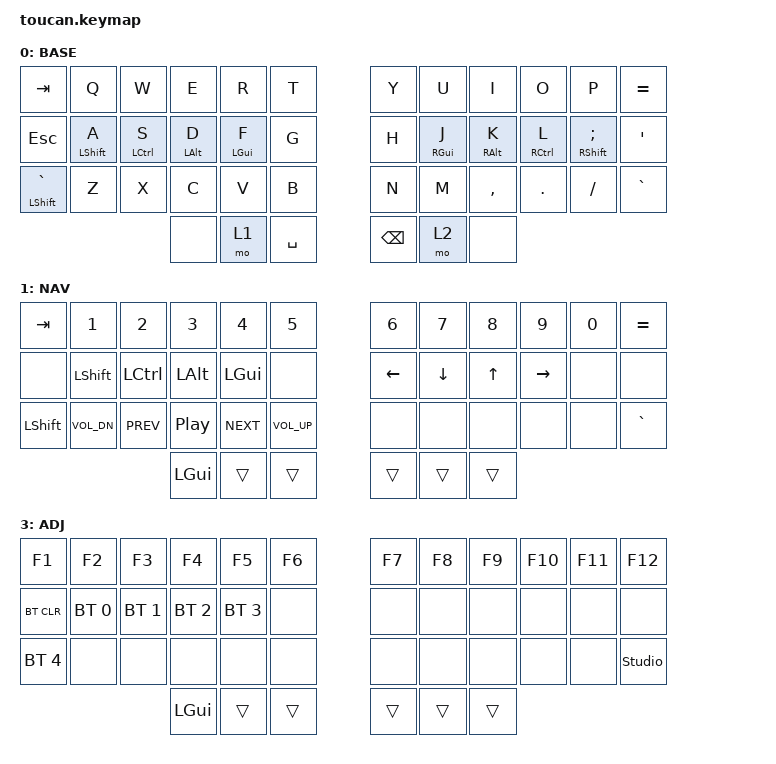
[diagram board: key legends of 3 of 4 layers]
#include <behaviors.dtsi>
#include <dt-bindings/zmk/keys.h>
#include <dt-bindings/zmk/bt.h>
#include <dt-bindings/zmk/outputs.h>

#define BASE 0
#define NAV  1
#define SYM  2
#define ADJ  3

#define SFT_A &mt LSHIFT A
#define CTRL_S &mt LCTRL S
#define ALT_D &mt LALT D
#define GUI_F &mt LGUI F

#define GUI_J &mt RGUI J
#define ALT_K &mt RALT K
#define CTRL_L &mt RCTRL L
#define SFT_SEMI &mt RSHIFT SEMI

#define SFT_GRAVE &mt LSHIFT GRAVE


&mt {
    flavor = "tap-preferred";
    tapping-term-ms = <180>;
};

/ {
    combos {
        compatible = "zmk,combos";
        combo_esc {
            timeout-ms = <50>;
            key-positions = <38 39>;
            bindings = <&kp RET>;
        };
    };
};

/ {
    conditional_layers {
        compatible = "zmk,conditional-layers";
        tri_layer {
            if-layers = <1 2>;
            then-layer = <3>;
        };
    };

    keymap {
        compatible = "zmk,keymap";

        base {
            display-name = "BASE";
            bindings = <
                &kp TAB   &kp Q &kp W  &kp E &kp R &kp T      &kp Y    &kp U  &kp I     &kp O   &kp P    &kp EQUAL
                &kp ESC   SFT_A CTRL_S ALT_D GUI_F &kp G      &kp H    GUI_J  ALT_K     CTRL_L  SFT_SEMI &kp SQT
                SFT_GRAVE &kp Z &kp X  &kp C &kp V &kp B      &kp N    &kp M  &kp COMMA &kp DOT &kp FSLH &kp GRAVE
                                       &none &mo 1 &kp SPACE  &kp BSPC &mo 2  &none
            >;
        };

        nav {
            display-name = "NAV";
            bindings = <
                &kp TAB     &kp N1          &kp N2       &kp N3           &kp N4       &kp N5                &kp N6   &kp N7   &kp N8 &kp N9    &kp N0 &kp EQUAL
                &none       &kp LSHIFT      &kp LCTRL    &kp LALT         &kp LGUI     &none                 &kp LEFT &kp DOWN &kp UP &kp RIGHT &none  &none
                &kp LSHFT   &kp C_VOL_DN    &kp C_PREV   &kp C_PLAY_PAUSE &kp C_NEXT   &kp C_VOL_UP          &none    &none    &none  &none     &none  &kp GRAVE
                                                         &kp LGUI         &trans       &trans                &trans   &trans   &trans
            >;
        };

        sym {
            display-name = "SYM";
            bindings = <
                &kp TAB   &kp EXCL    &kp AT     &kp HASH &kp DLLR &kp PRCNT                 &kp CARET &kp AMPS  &kp KP_MULTIPLY &kp LPAR &kp RPAR &kp BSPC
                &none     &kp LSHIFT  &kp LCTRL  &kp LALT &kp LGUI &none                     &kp MINUS &kp PLUS  &kp EQUAL       &kp LBKT &kp RBKT &kp BSLH &kp GRAVE
                &none     &none       &none      &none     &none   &none                     &kp UNDER &kp BSLH  &kp PIPE        &kp LBRC &kp RBRC &kp TILDE
                                                 &kp LGUI  &trans  &trans                    &trans   &trans    &trans
            >;
        };

        adj {
            display-name = "ADJ";
            bindings = <
                &kp F1       &kp F2       &kp F3       &kp F4       &kp F5                &kp F6 &kp F7 &kp F8 &kp F9 &kp F10 &kp F11 &kp F12 
                &bt BT_CLR   &bt BT_SEL 0 &bt BT_SEL 1 &bt BT_SEL 2 &bt BT_SEL 3          &none  &none  &none  &none  &none   &none   &none  
                &bt BT_SEL 4 &none        &none        &none        &none                 &none  &none  &none  &none  &none   &none   &studio_unlock  
                                          &kp LGUI     &trans       &trans                &trans   &trans    &trans
            >;
        };
        extra_1 {
                status = "reserved";
        };

        extra_2 {
                status = "reserved";
        };

        extra_3 {
                status = "reserved";
        };
    };
};
